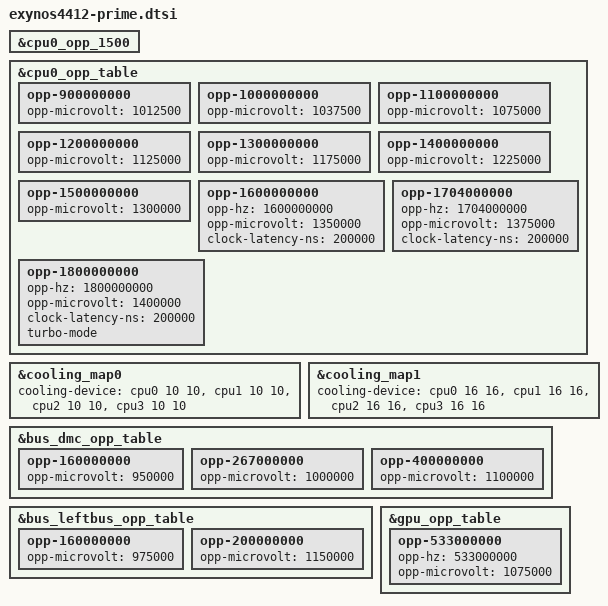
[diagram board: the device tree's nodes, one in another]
// SPDX-License-Identifier: GPL-2.0
/*
 * Samsung's Exynos4412 Prime SoC device tree source
 *
 * Copyright (c) 2016 Samsung Electronics Co., Ltd.
 *		http://www.samsung.com
 */

/*
 * Exynos4412 Prime SoC revision supports higher CPU frequencies than
 * non-Prime version.  Therefore we need to update OPPs table and
 * thermal maps accordingly.
 */

&cpu0_opp_1500 {
	/delete-property/turbo-mode;
};

&cpu0_opp_table {
	opp-900000000 {
		opp-microvolt = <1012500>;
	};
	opp-1000000000 {
		opp-microvolt = <1037500>;
	};
	opp-1100000000 {
		opp-microvolt = <1075000>;
	};
	opp-1200000000 {
		opp-microvolt = <1125000>;
	};
	opp-1300000000 {
		opp-microvolt = <1175000>;
	};
	opp-1400000000 {
		opp-microvolt = <1225000>;
	};
	opp-1500000000 {
		opp-microvolt = <1300000>;
	};

	opp-1600000000 {
		opp-hz = /bits/ 64 <1600000000>;
		opp-microvolt = <1350000>;
		clock-latency-ns = <200000>;
	};
	opp-1704000000 {
		opp-hz = /bits/ 64 <1704000000>;
		opp-microvolt = <1375000>;
		clock-latency-ns = <200000>;
	};
	opp-1800000000 {
		opp-hz = /bits/ 64 <1800000000>;
		opp-microvolt = <1400000>;
		clock-latency-ns = <200000>;
		turbo-mode;
	};
};

&cooling_map0 {
	cooling-device = <&cpu0 10 10>, <&cpu1 10 10>,
			 <&cpu2 10 10>, <&cpu3 10 10>;
};

&cooling_map1 {
	cooling-device = <&cpu0 16 16>, <&cpu1 16 16>,
			 <&cpu2 16 16>, <&cpu3 16 16>;
};

&bus_dmc_opp_table {
	opp-160000000 {
		opp-microvolt = <950000>;
	};
	opp-267000000 {
		opp-microvolt = <1000000>;
	};
	opp-400000000 {
		opp-microvolt = <1100000>;
	};
};

&bus_leftbus_opp_table {
	opp-160000000 {
		opp-microvolt = <975000>;
	};
	opp-200000000 {
		opp-microvolt = <1150000>;
	};
};

&gpu_opp_table {
	opp-533000000 {
		opp-hz = /bits/ 64 <533000000>;
		opp-microvolt = <1075000>;
	};
};
